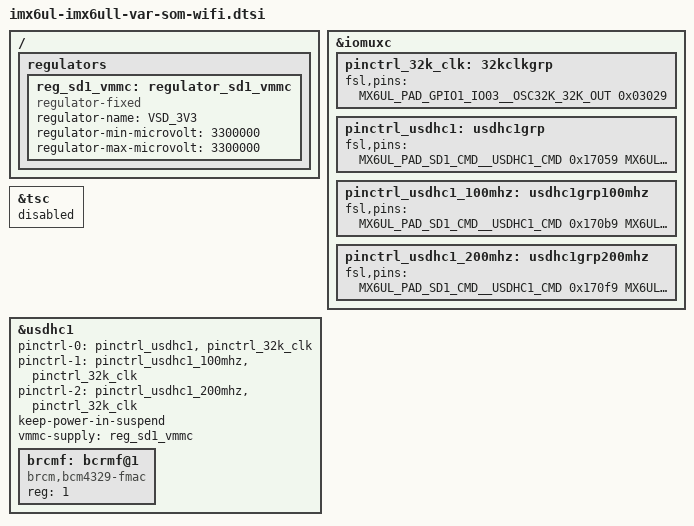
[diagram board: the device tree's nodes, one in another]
/*
 * Copyright (C) 2019 Variscite Ltd. - https://www.variscite.com
 *
 * This program is free software; you can redistribute it and/or modify
 * it under the terms of the GNU General Public License version 2 as
 * published by the Free Software Foundation.
 */

/ {
	regulators {
		reg_sd1_vmmc: regulator_sd1_vmmc {
			compatible = "regulator-fixed";
			regulator-name = "VSD_3V3";
			regulator-min-microvolt = <3300000>;
			regulator-max-microvolt = <3300000>;
		};
	};
};

&iomuxc {
	pinctrl_32k_clk: 32kclkgrp {
		fsl,pins = <
			MX6UL_PAD_GPIO1_IO03__OSC32K_32K_OUT	0x03029
		>;
	};

	pinctrl_usdhc1: usdhc1grp {
		fsl,pins = <
			MX6UL_PAD_SD1_CMD__USDHC1_CMD		0x17059
			MX6UL_PAD_SD1_CLK__USDHC1_CLK		0x17059
			MX6UL_PAD_SD1_DATA0__USDHC1_DATA0	0x17059
			MX6UL_PAD_SD1_DATA1__USDHC1_DATA1	0x17059
			MX6UL_PAD_SD1_DATA2__USDHC1_DATA2	0x17059
			MX6UL_PAD_SD1_DATA3__USDHC1_DATA3	0x17059
		>;
	};

	pinctrl_usdhc1_100mhz: usdhc1grp100mhz {
		fsl,pins = <
			MX6UL_PAD_SD1_CMD__USDHC1_CMD		0x170b9
			MX6UL_PAD_SD1_CLK__USDHC1_CLK		0x100b9
			MX6UL_PAD_SD1_DATA0__USDHC1_DATA0	0x170b9
			MX6UL_PAD_SD1_DATA1__USDHC1_DATA1	0x170b9
			MX6UL_PAD_SD1_DATA2__USDHC1_DATA2	0x170b9
			MX6UL_PAD_SD1_DATA3__USDHC1_DATA3	0x170b9
		>;
	};

	pinctrl_usdhc1_200mhz: usdhc1grp200mhz {
		fsl,pins = <
			MX6UL_PAD_SD1_CMD__USDHC1_CMD		0x170f9
			MX6UL_PAD_SD1_CLK__USDHC1_CLK		0x100f9
			MX6UL_PAD_SD1_DATA0__USDHC1_DATA0	0x170f9
			MX6UL_PAD_SD1_DATA1__USDHC1_DATA1	0x170f9
			MX6UL_PAD_SD1_DATA2__USDHC1_DATA2	0x170f9
			MX6UL_PAD_SD1_DATA3__USDHC1_DATA3	0x170f9
		>;
	};
};

&tsc {
	status = "disabled";
};

&usdhc1 {
	#address-cells = <1>;
	#size-cells = <0>;
	pinctrl-names = "default", "state_100mhz", "state_200mhz";
	pinctrl-0 = <&pinctrl_usdhc1>, <&pinctrl_32k_clk>;
	pinctrl-1 = <&pinctrl_usdhc1_100mhz>, <&pinctrl_32k_clk>;
	pinctrl-2 = <&pinctrl_usdhc1_200mhz>, <&pinctrl_32k_clk>;
	keep-power-in-suspend;
	vmmc-supply = <&reg_sd1_vmmc>;
	status = "okay";

	brcmf: bcrmf@1 {
		reg = <1>;
		compatible = "brcm,bcm4329-fmac";
	};
};
